VERSION ""

NS_ :

BS_:

BU_: XXX DSU HCU EPS IPAS CGW INTERCEPTOR EON

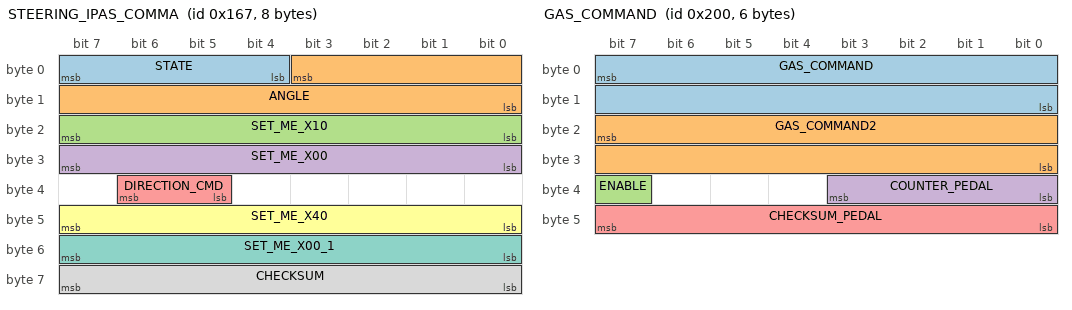
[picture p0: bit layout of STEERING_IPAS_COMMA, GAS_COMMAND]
BO_ 359 STEERING_IPAS_COMMA: 8 IPAS
 SG_ STATE : 7|4@0+ (1,0) [0|15] "" XXX
 SG_ ANGLE : 3|12@0- (1.5,0) [-510|510] "deg" XXX
 SG_ SET_ME_X10 : 23|8@0+ (1,0) [0|255] "" XXX
 SG_ SET_ME_X00 : 31|8@0+ (1,0) [0|255] "" XXX
 SG_ DIRECTION_CMD : 38|2@0+ (1,0) [0|3] "" XXX
 SG_ SET_ME_X40 : 47|8@0+ (1,0) [0|255] "" XXX
 SG_ SET_ME_X00_1 : 55|8@0+ (1,0) [0|255] "" XXX
 SG_ CHECKSUM : 63|8@0+ (1,0) [0|255] "" XXX

BO_ 512 GAS_COMMAND: 6 EON
 SG_ GAS_COMMAND : 7|16@0+ (0.159375,-75.555) [0|1] "" INTERCEPTOR
 SG_ GAS_COMMAND2 : 23|16@0+ (0.159375,-151.111) [0|1] "" INTERCEPTOR
 SG_ ENABLE : 39|1@0+ (1,0) [0|1] "" INTERCEPTOR
 SG_ COUNTER_PEDAL : 35|4@0+ (1,0) [0|15] "" INTERCEPTOR
 SG_ CHECKSUM_PEDAL : 47|8@0+ (1,0) [0|255] "" INTERCEPTOR

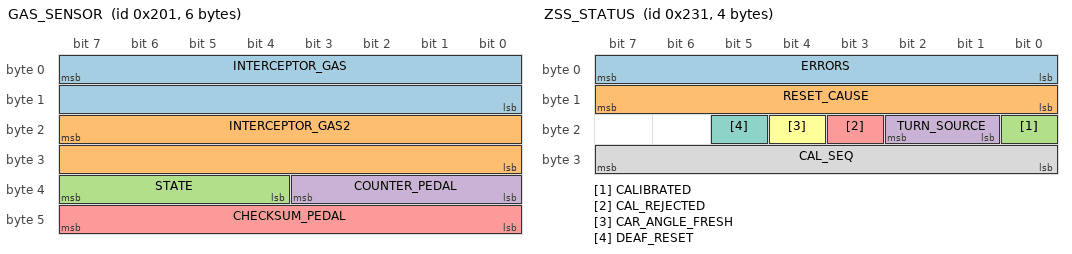
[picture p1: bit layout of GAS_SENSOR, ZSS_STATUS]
BO_ 513 GAS_SENSOR: 6 INTERCEPTOR
 SG_ INTERCEPTOR_GAS : 7|16@0+ (0.159375,-75.555) [0|1] "" EON
 SG_ INTERCEPTOR_GAS2 : 23|16@0+ (0.159375,-151.111) [0|1] "" EON
 SG_ STATE : 39|4@0+ (1,0) [0|15] "" EON
 SG_ COUNTER_PEDAL : 35|4@0+ (1,0) [0|15] "" EON
 SG_ CHECKSUM_PEDAL : 47|8@0+ (1,0) [0|255] "" EON

BO_ 35 SECONDARY_STEER_ANGLE: 8 XXX
 SG_ SIGN : 7|1@0+ (1,0) [0|1] "" XXX
 SG_ ANGLE : 23|16@0+ (1,0) [0|65535] "" XXX
 SG_ ZORRO_STEER : 7|32@0- (0.021973997,0) [-180|180] "" XXX

BO_ 561 ZSS_STATUS: 4 XXX
 SG_ ERRORS : 7|8@0+ (1,0) [0|255] "" XXX
 SG_ RESET_CAUSE : 15|8@0+ (1,0) [0|255] "" XXX
 SG_ CALIBRATED : 16|1@0+ (1,0) [0|1] "" XXX
 SG_ TURN_SOURCE : 18|2@0+ (1,0) [0|3] "" XXX
 SG_ CAL_REJECTED : 19|1@0+ (1,0) [0|1] "" XXX
 SG_ CAR_ANGLE_FRESH : 20|1@0+ (1,0) [0|1] "" XXX
 SG_ DEAF_RESET : 21|1@0+ (1,0) [0|1] "" XXX
 SG_ CAL_SEQ : 31|8@0+ (1,0) [0|255] "" XXX

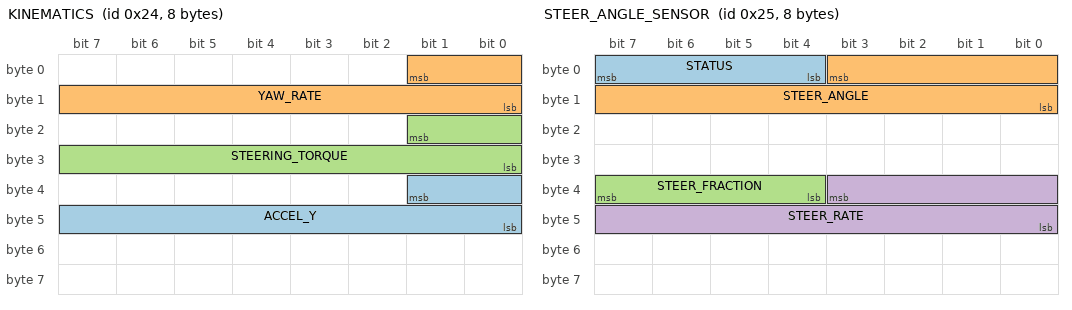
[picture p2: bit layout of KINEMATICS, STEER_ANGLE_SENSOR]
BO_ 36 KINEMATICS: 8 XXX
 SG_ ACCEL_Y : 33|10@0+ (0.03589,-18.375) [0|65535] "m/s^2" XXX
 SG_ YAW_RATE : 1|10@0+ (0.244,-125) [0|65535] "deg/sec" XXX
 SG_ STEERING_TORQUE : 17|10@0+ (1,-512) [0|65535] "" XXX

BO_ 37 STEER_ANGLE_SENSOR: 8 XXX
 SG_ STATUS : 7|4@0+ (1,0) [0|15] "" XXX
 SG_ STEER_ANGLE : 3|12@0- (1.5,0) [-500|500] "deg" XXX
 SG_ STEER_FRACTION : 39|4@0- (0.1,0) [-0.7|0.7] "deg" XXX
 SG_ STEER_RATE : 35|12@0- (1,0) [-2000|2000] "deg/s" XXX

BO_ 166 BRAKE: 8 XXX
 SG_ BRAKE_AMOUNT : 7|8@0+ (1,0) [0|255] "" XXX
 SG_ BRAKE_PEDAL : 23|8@0+ (1,0) [0|255] "" XXX

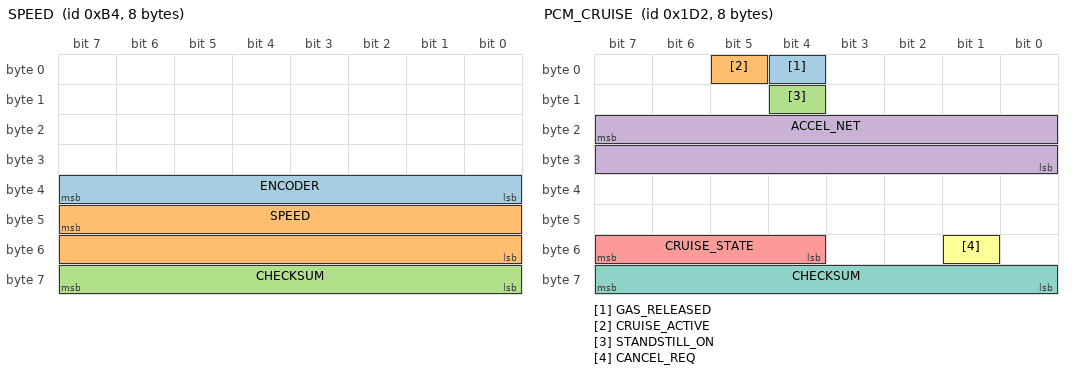
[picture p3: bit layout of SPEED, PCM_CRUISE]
BO_ 180 SPEED: 8 XXX
 SG_ ENCODER : 39|8@0+ (1,0) [0|255] "" XXX
 SG_ SPEED : 47|16@0+ (0.01,0) [0|250] "kph" XXX
 SG_ CHECKSUM : 63|8@0+ (1,0) [0|255] "" XXX

BO_ 552 ACCELEROMETER: 8 XXX
 SG_ ACCEL_Z : 22|15@0- (1,0) [0|32767] "" XXX
 SG_ ACCEL_X : 6|15@0- (0.001,0) [-20|20] "m/s2" XXX

BO_ 466 PCM_CRUISE: 8 XXX
 SG_ GAS_RELEASED : 4|1@0+ (1,0) [0|1] "" XXX
 SG_ CRUISE_ACTIVE : 5|1@0+ (1,0) [0|1] "" XXX
 SG_ STANDSTILL_ON : 12|1@0+ (1,0) [0|1] "" XXX
 SG_ ACCEL_NET : 23|16@0- (0.001,0) [-20|20] "m/s^2" XXX
 SG_ CRUISE_STATE : 55|4@0+ (1,0) [0|15] "" XXX
 SG_ CANCEL_REQ : 49|1@1+ (1,0) [0|1] "" XXX
 SG_ CHECKSUM : 63|8@0+ (1,0) [0|255] "" XXX

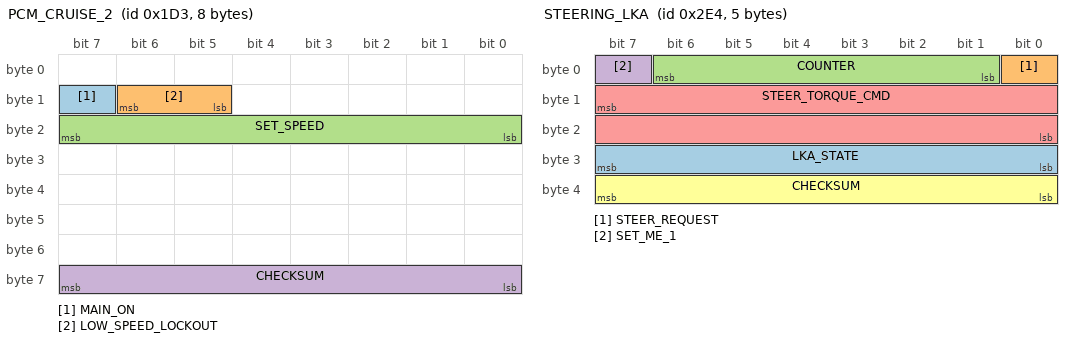
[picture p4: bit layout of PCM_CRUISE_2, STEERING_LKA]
BO_ 467 PCM_CRUISE_2: 8 XXX
 SG_ MAIN_ON : 15|1@0+ (1,0) [0|1] "" XXX
 SG_ LOW_SPEED_LOCKOUT : 14|2@0+ (1,0) [0|3] "" XXX
 SG_ SET_SPEED : 23|8@0+ (1,0) [0|255] "km/h" XXX
 SG_ CHECKSUM : 63|8@0+ (1,0) [0|255] "" XXX

BO_ 740 STEERING_LKA: 5 XXX
 SG_ LKA_STATE : 31|8@0+ (1,0) [0|255] "" XXX
 SG_ STEER_REQUEST : 0|1@0+ (1,0) [0|1] "" XXX
 SG_ COUNTER : 6|6@0+ (1,0) [0|63] "" XXX
 SG_ SET_ME_1 : 7|1@0+ (1,0) [0|1] "" XXX
 SG_ STEER_TORQUE_CMD : 15|16@0- (1,0) [0|65535] "" XXX
 SG_ CHECKSUM : 39|8@0+ (1,0) [0|255] "" XXX

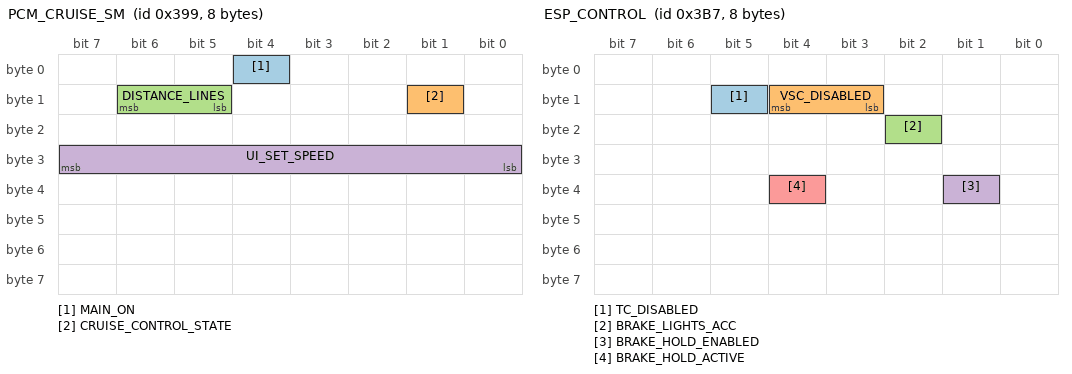
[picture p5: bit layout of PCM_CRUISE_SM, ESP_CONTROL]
BO_ 921 PCM_CRUISE_SM: 8 XXX
 SG_ MAIN_ON : 4|1@0+ (1,0) [0|1] "" XXX
 SG_ CRUISE_CONTROL_STATE : 9|1@0+ (1,0) [0|1] "" XXX
 SG_ DISTANCE_LINES : 14|2@0+ (1,0) [0|3] "" XXX
 SG_ UI_SET_SPEED : 31|8@0+ (1,0) [0|255] "" XXX

BO_ 951 ESP_CONTROL: 8 ESP
 SG_ TC_DISABLED : 13|1@0+ (1,0) [0|1] "" XXX
 SG_ VSC_DISABLED : 12|2@0+ (1,0) [0|1] "" XXX
 SG_ BRAKE_LIGHTS_ACC : 18|1@0+ (1,0) [0|1] "" XXX
 SG_ BRAKE_HOLD_ENABLED : 33|1@1+ (1,0) [0|1] "" XXX
 SG_ BRAKE_HOLD_ACTIVE : 36|1@0+ (1,0) [0|1] "" XXX

BO_ 1553 UI_SETTING: 8 XXX
 SG_ UNITS : 26|2@0+ (1,0) [0|3] "" XXX
 SG_ ODOMETER : 43|20@0+ (1,0) [0|1048575] "" XXX

BO_ 1556 BLINKERS_STATE: 2 XXX
 SG_ SIGNAL_LEFT : 7|8@0+ (1,0) [0|255] "" XXX
 SG_ SIGNAL_RIGHT : 15|8@0+ (1,0) [0|255] "" XXX

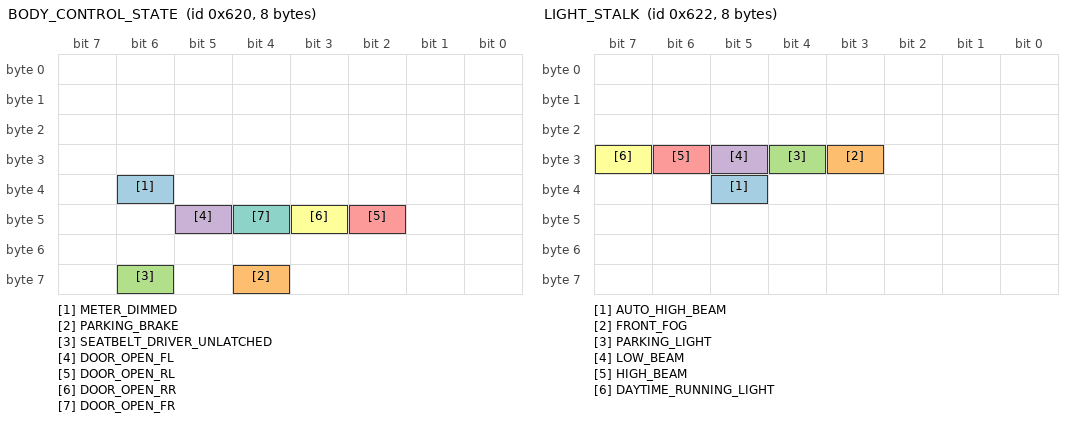
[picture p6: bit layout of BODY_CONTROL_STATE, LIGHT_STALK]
BO_ 1568 BODY_CONTROL_STATE: 8 XXX
 SG_ METER_DIMMED : 38|1@0+ (1,0) [0|1] "" XXX
 SG_ PARKING_BRAKE : 60|1@0+ (1,0) [0|1] "" XXX
 SG_ SEATBELT_DRIVER_UNLATCHED : 62|1@0+ (1,0) [0|1] "" XXX
 SG_ DOOR_OPEN_FL : 45|1@0+ (1,0) [0|1] "" XXX
 SG_ DOOR_OPEN_RL : 42|1@0+ (1,0) [0|1] "" XXX
 SG_ DOOR_OPEN_RR : 43|1@0+ (1,0) [0|1] "" XXX
 SG_ DOOR_OPEN_FR : 44|1@0+ (1,0) [0|1] "" XXX

BO_ 1570 LIGHT_STALK: 8 SCM
 SG_ AUTO_HIGH_BEAM : 37|1@0+ (1,0) [0|1] "" XXX
 SG_ FRONT_FOG : 27|1@0+ (1,0) [0|1] "" XXX
 SG_ PARKING_LIGHT : 28|1@0+ (1,0) [0|1] "" XXX
 SG_ LOW_BEAM : 29|1@0+ (1,0) [0|1] "" XXX
 SG_ HIGH_BEAM : 30|1@0+ (1,0) [0|1] "" XXX
 SG_ DAYTIME_RUNNING_LIGHT : 31|1@0+ (1,0) [0|1] "" XXX

BO_ 548 BRAKE_MODULE: 8 XXX
 SG_ BRAKE_PRESSURE : 43|12@0+ (1,0) [0|4047] "" XXX
 SG_ BRAKE_PRESSED : 5|1@0+ (1,0) [0|1] "" XXX

BO_ 705 GAS_PEDAL: 8 XXX
 SG_ GAS_RELEASED : 3|1@0+ (1,0) [0|1] "" XXX
 SG_ GAS_PEDAL : 55|8@0+ (0.005,0) [0|1] "" XXX

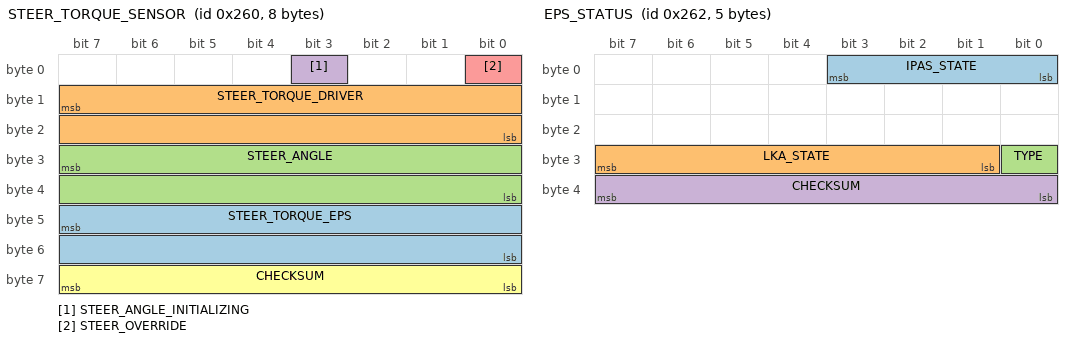
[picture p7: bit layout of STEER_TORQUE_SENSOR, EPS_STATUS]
BO_ 608 STEER_TORQUE_SENSOR: 8 XXX
 SG_ STEER_TORQUE_EPS : 47|16@0- (1,0) [-32768|32767] "" XXX
 SG_ STEER_TORQUE_DRIVER : 15|16@0- (1,0) [-32768|32767] "" XXX
 SG_ STEER_ANGLE : 31|16@0- (0.0573,0) [-500|500] "" XXX
 SG_ STEER_ANGLE_INITIALIZING : 3|1@0+ (1,0) [0|1] "" XXX
 SG_ STEER_OVERRIDE : 0|1@0+ (1,0) [0|1] "" XXX
 SG_ CHECKSUM : 63|8@0+ (1,0) [0|255] "" XXX

BO_ 610 EPS_STATUS: 5 EPS
 SG_ IPAS_STATE : 3|4@0+ (1,0) [0|15] "" XXX
 SG_ LKA_STATE : 31|7@0+ (1,0) [0|127] "" XXX
 SG_ TYPE : 24|1@0+ (1,0) [0|1] "" XXX
 SG_ CHECKSUM : 39|8@0+ (1,0) [0|255] "" XXX

BO_ 176 WHEEL_SPEEDS_FRONT: 8 XXX
 SG_ WHEEL_SPEED_FL : 23|16@0+ (0.01,0) [0|65535] "" XXX
 SG_ WHEEL_SPEED_FR : 7|16@0+ (0.01,0) [0|65535] "" XXX

BO_ 178 WHEEL_SPEEDS_REAR: 8 XXX
 SG_ WHEEL_SPEED_RL : 23|16@0+ (0.01,0) [0|65535] "" XXX
 SG_ WHEEL_SPEED_RR : 7|16@0+ (0.01,0) [0|65535] "" XXX

BO_ 720 GEAR_PACKET: 8 XXX
 SG_ GEAR : 20|5@0+ (1,0) [0|31] "" XXX
 SG_ GEAR_UNKNOWN_B7 : 23|1@0+ (1,0) [0|1] "" XXX

BO_ 956 GEAR_PACKET_LEGACY: 8 XXX
 SG_ GEAR : 13|6@0+ (1,0) [0|63] "" XXX
 SG_ SPORT_ON : 3|1@0+ (1,0) [0|1] "" XXX

BO_ 708 ENGINE_RPM: 8 XXX
 SG_ RPM : 7|16@0+ (0.78125,0) [0|51200] "rpm" XXX
 SG_ CHECK_ENGINE : 38|1@0+ (1,0) [0|1] "" XXX

BO_ 896 OUTSIDE_TEMP: 8 XXX
 SG_ OUTSIDE_TEMP_RAW : 55|8@0+ (1,0) [0|255] "" XXX

BO_ 948 ENGINE_TEMP: 8 XXX
 SG_ COOLANT_GAUGE : 23|8@0+ (1,0) [0|255] "" XXX

BO_ 1552 METER_SPEED: 8 XXX
 SG_ SPEED : 23|8@0+ (1,0) [0|255] "kph" XXX

CM_ BO_ 720 "Gear selector position, one-hot in byte 2, ~30Hz. 0x08 never observed;
0x00 appears while the lever is between detents.";
CM_ SG_ 720 GEAR_UNKNOWN_B7 "Not part of the gear code. Only ever seen set while in D.";
CM_ BO_ 956 GEAR_PACKET_LEGACY "Stock Toyota gear packet location. Present on the bus at
~83Hz but does not carry this car's gear selector, which is why GEAR_PACKET is 0x2D0.";
CM_ SG_ 36 ACCEL_Y "unit is tbd";
CM_ SG_ 36 YAW_RATE "verify";
CM_ SG_ 36 STEERING_TORQUE "does not seem the steer torque, tbd";
CM_ SG_ 560 BRAKE_PRESSED "another brake pressed?";
CM_ SG_ 951 BRAKE_LIGHTS_ACC "brake lights when ACC commands decel";
CM_ SG_ 1553 ODOMETER "Unit is dependent upon units signal";
CM_ SG_ 548 BRAKE_PRESSURE "seems prop to pedal force";
CM_ SG_ 610 TYPE "seems 1 on Corolla, 0 on all others";
CM_ SG_ 37 STATUS "china-sas board: 0 = angle valid (centre stored, tracking, both magnet sensors agree), 1 = invalid/fault/uncalibrated. The same board sends 0x23 on bus 0 only while valid.";
CM_ BO_ 561 "micro_sas status, 5Hz on bus 2 while the ignition is on. Layout from the micro_sas firmware's 0x231 sender: error flags, last reset cause, calibration status, calibration sequence.";
CM_ SG_ 561 CALIBRATED "A zero is stored in flash (set with ZERO on 0x232), so 0x23 is relative to true center across power cycles.";
CM_ SG_ 561 TURN_SOURCE "Where the turn count came from: 0 boot zero (uncalibrated), 1 restored from RAM after a warm reset, 2 resolved against the car's 0x25 angle, 3 calibrated but not yet confirmed by the car.";
CM_ SG_ 708 RPM "~41Hz. Scale confirmed by gearing: 4th with lockup gives ~2500 rpm at 100 km/h. 0x3B3 bytes 0-1 carry an identical copy.";
CM_ SG_ 708 CHECK_ENGINE "MIL. Dropped 80 ms after a Mode 04 clear, see selfdrive/car/glen/OBD_NOTES.md.";
CM_ SG_ 896 OUTSIDE_TEMP_RAW "~1Hz. Follows time of day across two months of routes (low ~9 on cold mornings, high ~66 on summer evenings). Scale unconfirmed, raw/2 = degC is a guess. 0x640 byte 5 is an inverse copy (r=-0.999).";
CM_ SG_ 948 COOLANT_GAUGE "~1Hz. Rises ~35 to ~178 over 12 min from a cold start, then holds 175-184. Floors at 32 on cold starts regardless of ambient, so it looks like gauge needle position rather than degC; raw/2 is a guess. OBD PID 05 is supported and would calibrate it.";
CM_ SG_ 1552 SPEED "~2Hz. Speed as shown on the stock cluster, reads ~0.8% below vEgo.";
VAL_ 513 STATE 5 "FAULT_TIMEOUT" 4 "FAULT_STARTUP" 3 "FAULT_SCE" 2 "FAULT_SEND" 1 "FAULT_BAD_CHECKSUM" 0 "NO_FAULT" ;
VAL_ 1553 UNITS 1 "km" 2 "miles" ;
VAL_ 1556 TURN_SIGNALS 3 "none" 2 "right" 1 "left" ;
VAL_ 610 IPAS_STATE 5 "override" 3 "enabled" 1 "disabled" ;
VAL_ 610 LKA_STATE 25 "temporary_fault" 9 "temporary_fault2" 5 "active" 1 "standby" ;
VAL_ 720 GEAR 1 "P" 2 "R" 4 "N" 16 "D";
VAL_ 956 GEAR 0 "D" 1 "S" 8 "N" 16 "R" 32 "P";
